AUTOSAR XML (schema 00044)
package /MICROSAR/BswM_swc/ComponentTypes
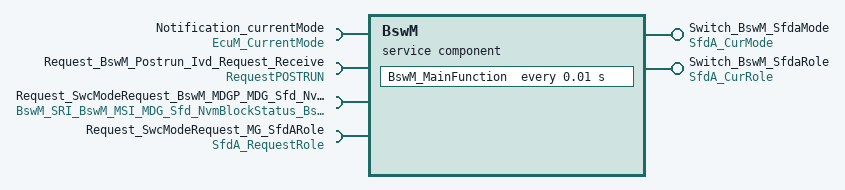
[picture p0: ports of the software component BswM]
  service sw component type BswM
    provide port Switch_BswM_SfdaMode: mode-switch-sender-com-spec{mode-group=MG_SfdAMode, queue-length=1}, provided-interface=SfdA_CurMode
    provide port Switch_BswM_SfdaRole: mode-switch-sender-com-spec{mode-group=MG_SfdARole, queue-length=1}, provided-interface=SfdA_CurRole
    4 x require port:
      Notification_currentMode: mode-switch-receiver-com-spec=currentMode, required-interface=EcuM_CurrentMode
      Request_BswM_Postrun_Ivd_Request_Receive: nonqueued-receiver-com-spec{data-element=Request, filter=data-filter-type=ALWAYS, init-value=IVD_REQUESTPOSTRUN_RELEASED}, required-interface=RequestPOSTRUN
      Request_SwcModeRequest_BswM_MDGP_MDG_Sfd_NvmBlockStatus: nonqueued-receiver-com-spec{data-element=requestedMode, filter=data-filter-type=ALWAYS, init-value=SFD_BLOCKS_NOT_INITIALIZED}, required-interface=BswM_SRI_BswM_MSI_MDG_Sfd_NvmBlockStatus_BswM_MDGP_MDG_Sfd_NvmBlockStatus
      Request_SwcModeRequest_MG_SfdARole: nonqueued-receiver-com-spec{data-element=Role, filter=data-filter-type=ALWAYS, init-value=SFDC_NO_ROLE}, required-interface=SfdA_RequestRole
    behavior BswMInternalBehavior: data-type-mapping=BswMMappingSet, included-data-type-set=data-type=BswM_MDG_Sfd_NvmBlockStatus
      timing event Timer_BswM_MainFunction: start-on-event=BswM_MainFunction, period=0.01
      port-api-options:
        enable-take-address=true, error-handling=NO-TRANSFORMER-ERROR-HANDLING, indirect-api=false, port=Notification_currentMode
        enable-take-address=true, error-handling=NO-TRANSFORMER-ERROR-HANDLING, indirect-api=false, port=Request_BswM_Postrun_Ivd_Request_Receive
        enable-take-address=true, error-handling=NO-TRANSFORMER-ERROR-HANDLING, indirect-api=false, port=Request_SwcModeRequest_BswM_MDGP_MDG_Sfd_NvmBlockStatus
        enable-take-address=true, error-handling=NO-TRANSFORMER-ERROR-HANDLING, indirect-api=false, port=Request_SwcModeRequest_MG_SfdARole
        enable-take-address=true, error-handling=NO-TRANSFORMER-ERROR-HANDLING, indirect-api=false, port=Switch_BswM_SfdaMode
        enable-take-address=true, error-handling=NO-TRANSFORMER-ERROR-HANDLING, indirect-api=false, port=Switch_BswM_SfdaRole
      runnable BswM_MainFunction: mode-access-point=Notification_currentMode.currentMode
        data-receive-point-by-arguments:
          access DataReceivePointBswM_MainFunction_Request_BswM_Postrun_Ivd_Request_Receive_Request: accessed-variable=Request_BswM_Postrun_Ivd_Request_Receive.Request
          access DataReceivePointBswM_MainFunction_Request_SwcModeRequest_BswM_MDGP_MDG_Sfd_NvmBlockStatus_requestedMode: accessed-variable=Request_SwcModeRequest_BswM_MDGP_MDG_Sfd_NvmBlockStatus.requestedMode
          access DataReceivePointBswM_MainFunction_Request_SwcModeRequest_MG_SfdARole_Role: accessed-variable=Request_SwcModeRequest_MG_SfdARole.Role
        mode switch point ModeSwitchPointBswM_MainFunction_Switch_BswM_SfdaMode_MG_SfdAMode: mode-group=Switch_BswM_SfdaMode.MG_SfdAMode
        mode switch point ModeSwitchPointBswM_MainFunction_Switch_BswM_SfdaRole_MG_SfdARole: mode-group=Switch_BswM_SfdaRole.MG_SfdARole
  swc implementation BswMImplementation: behavior=BswMInternalBehavior
    code-descriptors:
      code Default: artifact-descriptors=autosar-engineering-object=category=SWSRC
